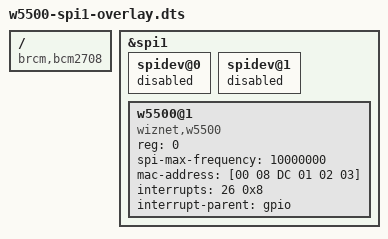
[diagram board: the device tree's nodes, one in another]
/dts-v1/;
/plugin/;

/ {
    compatible = "brcm,bcm2708";
    fragment@0 {
        target = <&spi1>;
        __overlay__ {
            #address-cells = <1>;
            #size-cells = <0>;

            status = "okay";

            spidev@0 {
                status = "disabled";
            };
            spidev@1 {
                status = "disabled";
            };
        };
    };

    fragment@1 {
        target = <&spi1>;
        __overlay__ {
            #address-cells = <1>;
            #size-cells = <0>;

            status = "okay";

            w5500@1 {
                compatible = "wiznet,w5500";
                reg = <0>;
                spi-max-frequency = <10000000>;
                mac-address = [00 08 DC 01 02 03];
                interrupts = <26 0x8>;
                interrupt-parent = <&gpio>;
                status = "okay";
            };
        };
    };
};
